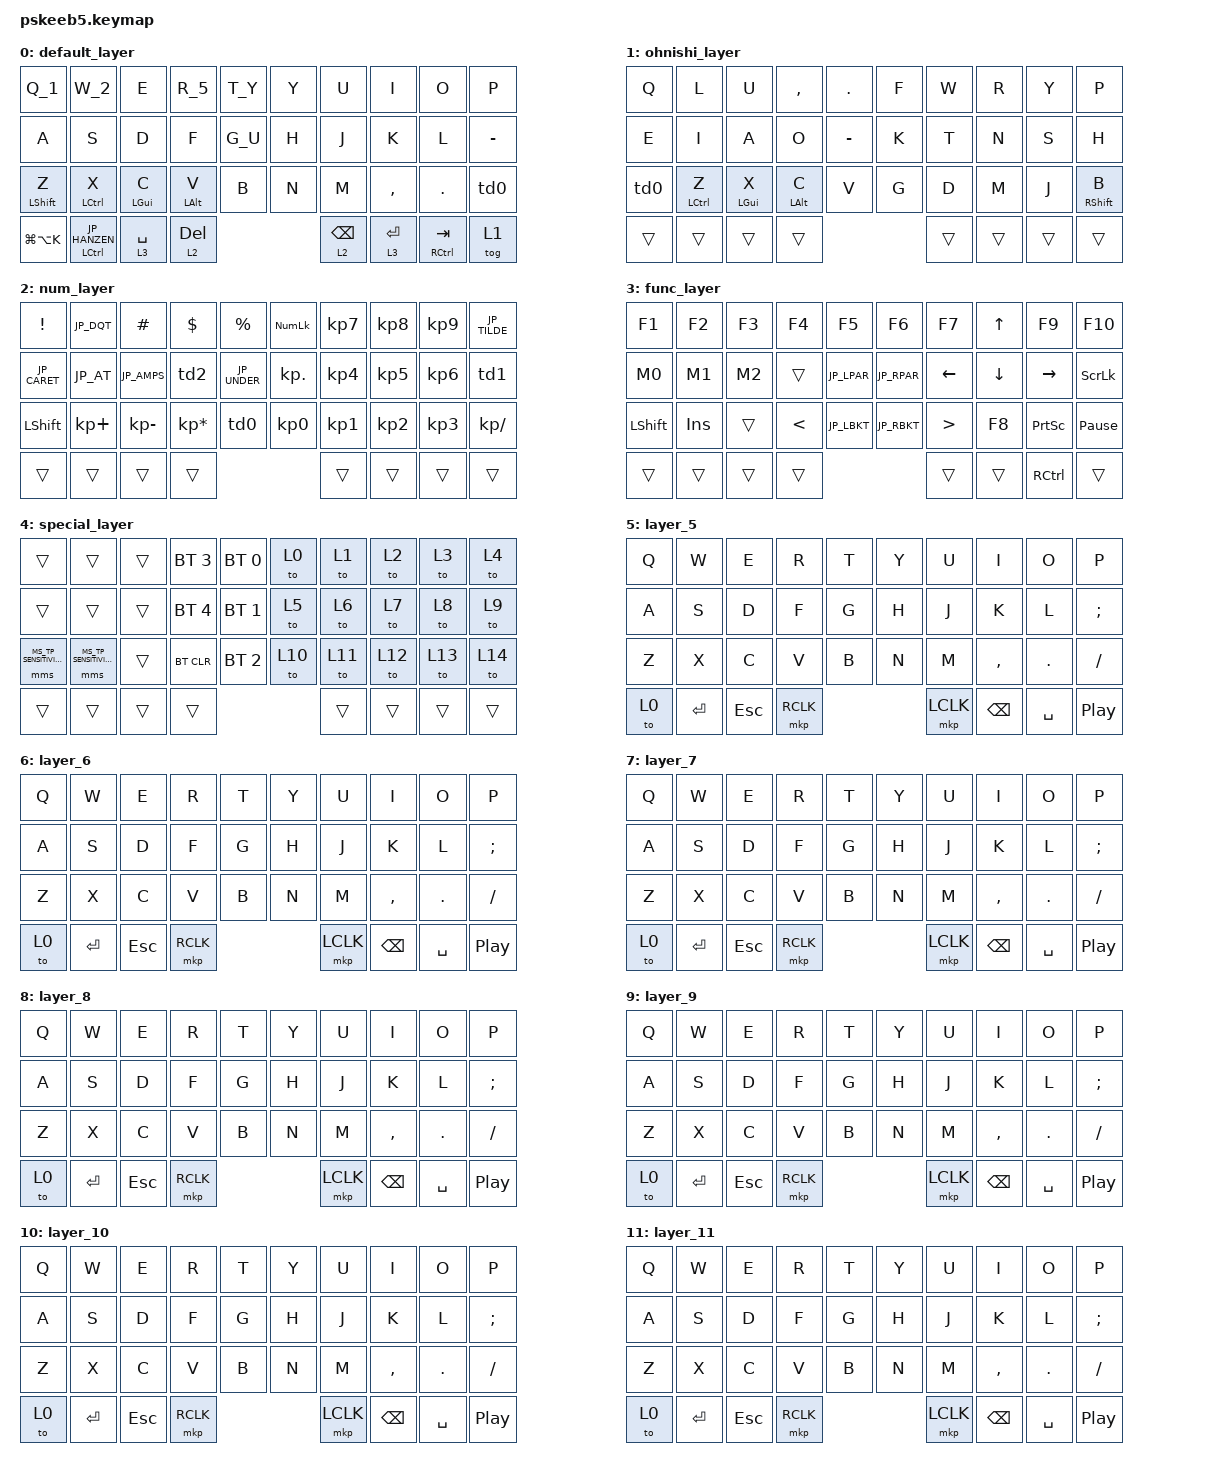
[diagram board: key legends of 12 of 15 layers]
// Copyright (c) 2022 The ZMK Contributors
// SPDX-License-Identifier: MIT

#include <behaviors.dtsi>
#include <dt-bindings/zmk/keys.h>
#include <dt-bindings/zmk/mouse.h>
#include <dt-bindings/zmk/bt.h>

// Home row mods macro
#define HRML(k1,k2,k3,k4) &ht LALT k1  &ht LSHFT k2  &ht LGUI k3  &ht LCTRL k4
#define HRMR(k1,k2,k3,k4) &ht RCTRL k1  &ht RGUI k2  &ht RSHFT k3  &ht RALT k4
#define LCS(keycode) APPLY_MODS(MOD_LCTL | MOD_LSFT, keycode)
#define LCG(keycode) APPLY_MODS(MOD_LCTL | MOD_LGUI, keycode)

// Rotary Endocer for mouse scrolling
#define ROT_MSC_VAL 280
#define ROT_MSC_SUP MOVE_Y(ROT_MSC_VAL)
#define ROT_MSC_SDN MOVE_Y(-ROT_MSC_VAL)
#define ROT_MSC_SLT MOVE_X(-ROT_MSC_VAL)
#define ROT_MSC_SRT MOVE_X(ROT_MSC_VAL)

// OS設定を日本語キーボードのまま使用するための変換定義
#define JP_DQT          AT                // "
#define JP_AMPS         CARET             // &
#define JP_SQT          AMPERSAND         // '
#define JP_EQUAL        UNDER             // =
#define JP_CARET        EQUAL             // ^
#define JP_YEN          0x89              // ¥
#define JP_PLUS         COLON             // +
#define JP_TILDE        PLUS              // ~
#define JP_PIPE         LS(0x89)          // |
#define JP_AT           LEFT_BRACKET      // @
#define JP_COLON        SINGLE_QUOTE      // :
#define JP_ASTRK        DOUBLE_QUOTES     // *
#define JP_GRAVE        LEFT_BRACE        // `
#define JP_UNDER        LS(0x87)          // _
#define JP_LBKT         RIGHT_BRACKET     // [
#define JP_RBKT         BACKSLASH         // ]
#define JP_LPAR         ASTERISK          // (
#define JP_RPAR         LEFT_PARENTHESIS  // )
#define JP_LBRC         RIGHT_BRACE       // {
#define JP_RBRC         PIPE              // }
#define JP_KANA         LANGUAGE_1        // かな
#define JP_EISU         LANGUAGE_2        // 英数
#define JP_HANZEN       GRAVE             // 半角/全角

#include <behaviors/mouse_setting.dtsi>
#include <dt-bindings/zmk/mouse_settings.h>
#define U_MSS_TP_S_I &mms MS_TP_SENSITIVITY_INCR
#define U_MSS_TP_S_D &mms MS_TP_SENSITIVITY_DECR

/ {
    behaviors {
        ht: hold_tap {
            display-name = "Hold Tap";
            label = "hold_tap";
            compatible = "zmk,behavior-hold-tap";
            #binding-cells = <2>;
            flavor = "balanced";
            tapping-term-ms = <220>;
            quick-tap-ms = <200>;
            // global-quick-tap;
            bindings = <&kp>, <&kp>;
        };
        lt: layer_tap {
            display-name = "Layer Tap";
            compatible = "zmk,behavior-hold-tap";
            label = "LAYER_TAP";
            #binding-cells = <2>;
            // flavor = "balanced";
            tapping-term-ms = <200>;
            quick-tap-ms = <200>;
            // global-quick-tap;
            bindings = <&mo>, <&kp>;
        };
        rot_msc: sensor_rotate_msc {
            compatible = "zmk,behavior-sensor-rotate-var";
            #sensor-binding-cells = <2>;
            bindings = <&msc>, <&msc>;
            tap-ms = <20>;
        };
        td0: tap_dance_0 {
            compatible = "zmk,behavior-tap-dance";
            #binding-cells = <0>;
            tapping-term-ms = <200>;
            bindings = <&ht LSHFT FSLH>, <&kp JP_YEN>;
        };
        td1: tap_dance_1 {
            compatible = "zmk,behavior-tap-dance";
            #binding-cells = <0>;
            tapping-term-ms = <200>;
            bindings = <&kp JP_COLON>, <&kp SEMI>;
        };
        td2: tap_dance_2 {
            compatible = "zmk,behavior-tap-dance";
            #binding-cells = <0>;
            tapping-term-ms = <200>;
            bindings = <&kp JP_SQT>, <&kp JP_GRAVE>;
        };
        Q_1: Q_ctrl1 {
            compatible = "zmk,behavior-mod-morph";
            #binding-cells = <0>;
            bindings = <&kp Q>, <&kp N1>;
            mods = <(MOD_LCTL|MOD_RCTL)>;
            keep-mods = <(MOD_LCTL|MOD_RCTL)>;
        };
        W_2: W_ctrl2 {
            compatible = "zmk,behavior-mod-morph";
            #binding-cells = <0>;
            bindings = <&kp W>, <&kp N2>;
            mods = <(MOD_LCTL|MOD_RCTL)>;
            keep-mods = <(MOD_LCTL|MOD_RCTL)>;
        };
        R_5: R_ctrl5 {
            compatible = "zmk,behavior-mod-morph";
            #binding-cells = <0>;
            bindings = <&kp R>, <&kp N5>;
            mods = <(MOD_LCTL|MOD_RCTL)>;
            keep-mods = <(MOD_LCTL|MOD_RCTL)>;
        };
        T_Y: T_ctrlY {
            compatible = "zmk,behavior-mod-morph";
            #binding-cells = <0>;
            bindings = <&kp T>, <&kp Y>;
            mods = <(MOD_LCTL|MOD_RCTL)>;
            keep-mods = <(MOD_LCTL|MOD_RCTL)>;
        };
        G_U: G_ctrlU {
            compatible = "zmk,behavior-mod-morph";
            #binding-cells = <0>;
            bindings = <&kp G>, <&kp U>;
            mods = <(MOD_LCTL|MOD_RCTL)>;
            keep-mods = <(MOD_LCTL|MOD_RCTL)>;
        };
        //gresc: grave_escape {
        //    compatible = "zmk,behavior-mod-morph";
        //    #binding-cells = <0>;
        //    bindings = <&kp ESC>, <&kp GRAVE>;
        //    mods = <(MOD_LGUI|MOD_LSFT|MOD_RGUI|MOD_RSFT)>;
        //};
    };


    combos {
        compatible = "zmk,combos";
        //combo_tab {
        //    timeout-ms = <50>;
        //    key-positions = <2 3>;
        //    bindings = <&kp TAB>;
        //};
        combo_esc {
            timeout-ms = <50>;
            key-positions = <0 1>;
            bindings = <&kp ESC>;
        };
        left_click {
            timeout-ms = <50>;
            key-positions = <34 35>;
            bindings = <&mkp LCLK>;
        };
        right_click {
            timeout-ms = <50>;
            key-positions = <35 36>;
            bindings = <&mkp RCLK>;
        };
        middle_click {
            timeout-ms = <50>;
            key-positions = <33 34>;
            bindings = <&mkp MCLK>;
        };
    };

    conditional_layers {
        compatible = "zmk,conditional-layers";
        special_layer {
            if-layers = <2 3>;
            then-layer = <4>;
        };
    };

    macros {
        //win_sleep: win_sleep {
        //    compatible = "zmk,behavior-macro";
        //    #binding-cells = <0>;
        //    bindings
        //        = <&kp LG(X)>   // Opens the quick menu
        //        , <&macro_wait_time 50>    // Small delay for menu
        //        , <&kp U>       // "Shut down or sign out"
        //        , <&macro_wait_time 50>    // Delay
        //        , <&kp S>;      // "Sleep"
        //};
        M0: M0 {
            compatible = "zmk,behavior-macro";
            #binding-cells = <0>;
            bindings
                = <&kp INT5 &kp N6 &kp N1 &kp N0 &kp N8 &kp N1 &kp N1>;
        };
        M1: M1 {
            compatible = "zmk,behavior-macro";
            #binding-cells = <0>;
            bindings
                = <&kp INT5 &kp LS(R) &kp EXCL &kp K &kp K &kp A &kp N &kp A &kp K &kp N0>;
        };
        M2: M2 {
            compatible = "zmk,behavior-macro";
            #binding-cells = <0>;
            wait-ms = <10>;
            tap-ms = <10>;
            bindings
                = <&kp INT5 &kp W &kp A &kp T &kp A &kp N &kp A &kp B &kp E &kp DOT>
                , <&kp N5 &kp N3 &kp C &kp DOT &kp Y &kp U &kp JP_AT>
                , <&kp J &kp P &kp DOT>
                , <&kp N &kp I &kp P &kp P &kp O &kp N &kp S &kp T &kp E &kp E &kp L &kp DOT>
                , <&kp C &kp O &kp M>;
        };
    };

    keymap {
        compatible = "zmk,keymap";
        default_layer {
            bindings = <
        //╭──────────┬──────────┬──────────┬──────────┬──────────╮   ╭──────────┬──────────┬──────────┬──────────┬──────────╮
        //│  Q       │  W       │  E       │  R       │  T       │   │  Y       │  U       │  I       │  O       │  P       │
            &Q_1       &W_2       &kp E      &R_5       &T_Y           &kp Y      &kp U      &kp I      &kp O      &kp P
        //├──────────┼──────────┼──────────┼──────────┼──────────┤   ├──────────┼──────────┼──────────┼──────────┼──────────┤
        //│  A       │  S       │  D       │  F       │  G       │   │  H       │  J       │  K       │  L       │ - =      │
            &kp A      &kp S      &kp D      &kp F      &G_U           &kp H      &kp J      &kp K      &kp L      &kp MINUS
        //├──────────┼──────────┼──────────┼──────────┼──────────┤   ├──────────┼──────────┼──────────┼──────────┼──────────┤
        //│  Z       │  X       │  C       │  V       │  B       │   │  N       │  M       │ , <      │ . >      │ / ? \    │
           &ht LSHFT Z &ht LCTRL X &ht LGUI C &ht LALT V &kp B         &kp N      &kp M      &kp COMMA &kp DOT     &td0
        //╰──────────┴──────────┴──────────┼──────────┼──────────┤   ├──────────┼──────────┼──────────┴──────────┴──────────╯
             &kp LG(LA(K))  &ht LCTRL JP_HANZEN &lt 3 SPACE &lt 2 DEL     &lt 2 BSPC &lt 3 ENTER &ht RCTRL TAB &tog 1
        //                                 ╰──────────┴──────────╯   ╰──────────┴──────────╯
            >;
            // sensor-bindings = <&rot_msc ROT_MSC_SUP ROT_MSC_SDN &rot_msc ROT_MSC_SLT ROT_MSC_SRT>;
            sensor-bindings = <&inc_dec_kp C_VOL_DN C_VOL_UP &rot_msc ROT_MSC_SDN ROT_MSC_SUP>;
        };

        ohnishi_layer {
            bindings = <
        //╭──────────┬──────────┬──────────┬──────────┬──────────╮   ╭──────────┬──────────┬──────────┬──────────┬──────────╮
        //│  Q       │  L       │  U       │ , <      │ . >      │   │  F       │  W       │  R       │  Y       │  P       │
            &kp Q      &kp L      &kp U      &kp COMMA  &kp DOT        &kp F      &kp W      &kp R      &kp Y      &kp P
        //├──────────┼──────────┼──────────┼──────────┼──────────┤   ├──────────┼──────────┼──────────┼──────────┼──────────┤
        //│  E       │  I       │  A       │  O       │ - =      │   │  K       │  T       │  N       │  S       │  H       │
            &kp E      &kp I      &kp A      &kp O      &kp MINUS      &kp K      &kp T      &kp N      &kp S      &kp H
        //├──────────┼──────────┼──────────┼──────────┼──────────┤   ├──────────┼──────────┼──────────┼──────────┼──────────┤
        //│ / ? \    │  Z       │  X       │  C       │  V       │   │  G       │  D       │  M       │  J       │  B       │
            &td0       &ht LCTRL Z &ht LGUI X &ht LALT C &kp V         &kp G      &kp D      &kp M      &kp J     &ht RSHFT B
        //╰──────────┴──────────┴──────────┼──────────┼──────────┤   ├──────────┼──────────┼──────────┴──────────┴──────────╯
                       &trans     &trans     &trans     &trans         &trans     &trans     &trans     &trans  
        //                                 ╰──────────┴──────────╯   ╰──────────┴──────────╯
            >;
            // sensor-bindings = <&rot_msc ROT_MSC_SUP ROT_MSC_SDN &rot_msc ROT_MSC_SLT ROT_MSC_SRT>;
            sensor-bindings = <&inc_dec_kp C_VOL_DN C_VOL_UP &rot_msc ROT_MSC_SDN ROT_MSC_SUP>;
        };

        num_layer {
            bindings = <
        //╭──────────┬──────────┬──────────┬──────────┬──────────╮   ╭──────────┬──────────┬──────────┬──────────┬──────────╮
        //│  !       │  "       │  #       │  $       │  %       │   │ NUM LOCK │  7       │  8       │  9       │  ~       │
            &kp EXCL  &kp JP_DQT  &kp HASH   &kp DLLR   &kp PRCNT      &kp KP_NUM &kp KP_N7  &kp KP_N8  &kp KP_N9  &kp JP_TILDE
        //├──────────┼──────────┼──────────┼──────────┼──────────┤   ├──────────┼──────────┼──────────┼──────────┼──────────┤
        //│  ^       │  @       │  &       │  ' `     │  _       │   │  .       │  4       │  5       │  6       │  : ;     │
          &kp JP_CARET &kp JP_AT  &kp JP_AMPS &td2      &kp JP_UNDER   &kp KP_DOT &kp KP_N4  &kp KP_N5  &kp KP_N6  &td1
        //├──────────┼──────────┼──────────┼──────────┼──────────┤   ├──────────┼──────────┼──────────┼──────────┼──────────┤
        //│  LSHIFT  │  +       │  -       │  *       │  / ? \   │   │  0       │  1       │  2       │  3       │  /       │
            &kp LSHFT  &kp KP_PLUS &kp KP_MINUS &kp KP_MULTIPLY &td0   &kp KP_N0  &kp KP_N1  &kp KP_N2  &kp KP_N3  &kp KP_DIVIDE 
        //╰──────────┴──────────┴──────────┼──────────┼──────────┤   ├──────────┼──────────┼──────────┴──────────┴──────────╯
                       &trans     &trans     &trans     &trans         &trans     &trans     &trans     &trans
        //                                 ╰──────────┴──────────╯   ╰──────────┴──────────╯
            >;
            sensor-bindings = <&inc_dec_kp C_VOL_DN C_VOL_UP &inc_dec_kp LEFT RIGHT>;
        };

        func_layer {
            bindings = <
        //╭──────────┬──────────┬──────────┬──────────┬──────────╮   ╭──────────┬──────────┬──────────┬──────────┬──────────╮
        //│ F1       │ F2       │ F3       │ F4       │ F5       │   │ F6       │ F7       │ Up       │ F9       │ F10      │
            &kp F1     &kp F2     &kp F3     &kp F4     &kp F5         &kp F6     &kp F7     &kp UP     &kp F9     &kp F10 
        //├──────────┼──────────┼──────────┼──────────┼──────────┤   ├──────────┼──────────┼──────────┼──────────┼──────────┤
        //│ M0       │ M1       │ M2       │          │  (       │   │  )       │ LEFT     │ DOWN     │ RIGHT    │ ScrLock  │
            &M0        &M1        &M2        &trans     &kp JP_LPAR   &kp JP_RPAR &kp LEFT   &kp DOWN   &kp RIGHT  &kp SLCK 
        //├──────────┼──────────┼──────────┼──────────┼──────────┤   ├──────────┼──────────┼──────────┼──────────┼──────────┤
        //│ LSHIFT   │ INS      │          │  <       │  [       │   │  ]       │  >       │ F8       │ PrtScr   │ Pause    │
            &kp LSHFT  &kp INS    &trans     &kp LT     &kp JP_LBKT   &kp JP_RBKT &kp GT     &kp F8     &kp PSCRN  &kp PAUSE_BREAK
        //╰──────────┴──────────┴──────────┼──────────┼──────────┤   ├──────────┼──────────┼──────────┴──────────┴──────────╯
                        &trans     &trans    &trans     &trans         &trans     &trans     &kp RCTRL  &trans
        //                                 ╰──────────┴──────────╯   ╰──────────┴──────────╯
            >;
            sensor-bindings = <&inc_dec_kp C_VOL_DN C_VOL_UP &inc_dec_kp LEFT RIGHT>;
        };

        special_layer {
            bindings = <
        //╭──────────────┬──────────────┬──────────┬─────────────┬────────────╮   ╭──────────┬──────────┬──────────┬──────────┬──────────╮
        //│              │              │          │ PROFILE 3   │PROFILE 0   │   │          │          │          │          │          │
           &trans           &trans        &trans     &bt BT_SEL 3 &bt BT_SEL 0      &to 0     &to 1       &to 2      &to 3      &to 4
        //├──────────────┼──────────────┼──────────┼─────────────┼────────────┤   ├──────────┼──────────┼──────────┼──────────┼──────────┤
        //│              │              │          │ PROFILE 4   │PROFILE 1   │   │          │          │          │          │          │
           &trans           &trans        &trans    &bt BT_SEL 4 &bt BT_SEL 1       &to 5     &to 6       &to 7      &to 8      &to 9
        //├──────────────┼──────────────┼──────────┼─────────────┼────────────┤   ├──────────┼──────────┼──────────┼──────────┼──────────┤
        //│              │              │          │ CLEAR BT    │PROFILE 2   │   │          │          │          │          │          │
           U_MSS_TP_S_D    U_MSS_TP_S_I   &trans   &bt BT_CLR   &bt BT_SEL 2        &to 10    &to 11      &to 12     &to 13     &to 14
        //╰──────────────┴──────────────┴──────────┼─────────────┼────────────┤   ├──────────┼──────────┼──────────┴──────────┴──────────╯
                       &trans     &trans    &trans     &trans             &trans     &trans     &trans     &trans
        //                                 ╰─────────────┴──────────╯   ╰──────────┴──────────╯
            >;
            sensor-bindings = <&inc_dec_kp C_VOL_DN C_VOL_UP &inc_dec_kp LEFT RIGHT>;
        };

        layer_5 {
            bindings = <
        //╭──────────┬──────────┬──────────┬──────────┬──────────╮   ╭──────────┬──────────┬──────────┬──────────┬──────────╮
        //│  Q       │  W       │  E       │  R       │  T       │   │  Y       │  U       │  I       │  O       │  P       │
            &kp Q      &kp W      &kp E      &kp R      &kp T          &kp Y      &kp U      &kp I      &kp O      &kp P
        //├──────────┼──────────┼──────────┼──────────┼──────────┤   ├──────────┼──────────┼──────────┼──────────┼──────────┤
        //│  A       │  S       │  D       │  F       │  G       │   │  H       │  J       │  K       │  L       │ ; :      │
            &kp A      &kp S      &kp D      &kp F      &kp G          &kp H      &kp J      &kp K      &kp L      &kp SEMI
        //├──────────┼──────────┼──────────┼──────────┼──────────┤   ├──────────┼──────────┼──────────┼──────────┼──────────┤
        //│  Z       │  X       │  C       │  V       │  B       │   │  N       │  M       │ , <      │ . >      │ / ?      │
            &kp Z      &kp X      &kp C      &kp V      &kp B          &kp N      &kp M      &kp COMMA  &kp DOT    &kp FSLH
        //╰──────────┴──────────┴──────────┼──────────┼──────────┤   ├──────────┼──────────┼──────────┴──────────┴──────────╯
                       &to 0      &kp ENTER  &kp ESC    &mkp RCLK      &mkp LCLK  &kp BSPC   &kp SPACE  &kp C_PP
        //                                 ╰──────────┴──────────╯   ╰──────────┴──────────╯
            >;
            sensor-bindings = <&inc_dec_kp C_VOL_DN C_VOL_UP &inc_dec_kp LEFT RIGHT>;
        };

        layer_6 {
            bindings = <
        //╭──────────┬──────────┬──────────┬──────────┬──────────╮   ╭──────────┬──────────┬──────────┬──────────┬──────────╮
        //│  Q       │  W       │  E       │  R       │  T       │   │  Y       │  U       │  I       │  O       │  P       │
            &kp Q      &kp W      &kp E      &kp R      &kp T          &kp Y      &kp U      &kp I      &kp O      &kp P
        //├──────────┼──────────┼──────────┼──────────┼──────────┤   ├──────────┼──────────┼──────────┼──────────┼──────────┤
        //│  A       │  S       │  D       │  F       │  G       │   │  H       │  J       │  K       │  L       │ ; :      │
            &kp A      &kp S      &kp D      &kp F      &kp G          &kp H      &kp J      &kp K      &kp L      &kp SEMI
        //├──────────┼──────────┼──────────┼──────────┼──────────┤   ├──────────┼──────────┼──────────┼──────────┼──────────┤
        //│  Z       │  X       │  C       │  V       │  B       │   │  N       │  M       │ , <      │ . >      │ / ?      │
            &kp Z      &kp X      &kp C      &kp V      &kp B          &kp N      &kp M      &kp COMMA  &kp DOT    &kp FSLH
        //╰──────────┴──────────┴──────────┼──────────┼──────────┤   ├──────────┼──────────┼──────────┴──────────┴──────────╯
                       &to 0      &kp ENTER  &kp ESC    &mkp RCLK      &mkp LCLK  &kp BSPC   &kp SPACE  &kp C_PP
        //                                 ╰──────────┴──────────╯   ╰──────────┴──────────╯
            >;
            sensor-bindings = <&inc_dec_kp C_VOL_DN C_VOL_UP &inc_dec_kp LEFT RIGHT>;
        };

        layer_7 {
            bindings = <
        //╭──────────┬──────────┬──────────┬──────────┬──────────╮   ╭──────────┬──────────┬──────────┬──────────┬──────────╮
        //│  Q       │  W       │  E       │  R       │  T       │   │  Y       │  U       │  I       │  O       │  P       │
            &kp Q      &kp W      &kp E      &kp R      &kp T          &kp Y      &kp U      &kp I      &kp O      &kp P
        //├──────────┼──────────┼──────────┼──────────┼──────────┤   ├──────────┼──────────┼──────────┼──────────┼──────────┤
        //│  A       │  S       │  D       │  F       │  G       │   │  H       │  J       │  K       │  L       │ ; :      │
            &kp A      &kp S      &kp D      &kp F      &kp G          &kp H      &kp J      &kp K      &kp L      &kp SEMI
        //├──────────┼──────────┼──────────┼──────────┼──────────┤   ├──────────┼──────────┼──────────┼──────────┼──────────┤
        //│  Z       │  X       │  C       │  V       │  B       │   │  N       │  M       │ , <      │ . >      │ / ?      │
            &kp Z      &kp X      &kp C      &kp V      &kp B          &kp N      &kp M      &kp COMMA  &kp DOT    &kp FSLH
        //╰──────────┴──────────┴──────────┼──────────┼──────────┤   ├──────────┼──────────┼──────────┴──────────┴──────────╯
                       &to 0      &kp ENTER  &kp ESC    &mkp RCLK      &mkp LCLK  &kp BSPC   &kp SPACE  &kp C_PP
        //                                 ╰──────────┴──────────╯   ╰──────────┴──────────╯
            >;
            sensor-bindings = <&inc_dec_kp C_VOL_DN C_VOL_UP &inc_dec_kp LEFT RIGHT>;
        };

        layer_8 {
            bindings = <
        //╭──────────┬──────────┬──────────┬──────────┬──────────╮   ╭──────────┬──────────┬──────────┬──────────┬──────────╮
        //│  Q       │  W       │  E       │  R       │  T       │   │  Y       │  U       │  I       │  O       │  P       │
            &kp Q      &kp W      &kp E      &kp R      &kp T          &kp Y      &kp U      &kp I      &kp O      &kp P
        //├──────────┼──────────┼──────────┼──────────┼──────────┤   ├──────────┼──────────┼──────────┼──────────┼──────────┤
        //│  A       │  S       │  D       │  F       │  G       │   │  H       │  J       │  K       │  L       │ ; :      │
            &kp A      &kp S      &kp D      &kp F      &kp G          &kp H      &kp J      &kp K      &kp L      &kp SEMI
        //├──────────┼──────────┼──────────┼──────────┼──────────┤   ├──────────┼──────────┼──────────┼──────────┼──────────┤
        //│  Z       │  X       │  C       │  V       │  B       │   │  N       │  M       │ , <      │ . >      │ / ?      │
            &kp Z      &kp X      &kp C      &kp V      &kp B          &kp N      &kp M      &kp COMMA  &kp DOT    &kp FSLH
        //╰──────────┴──────────┴──────────┼──────────┼──────────┤   ├──────────┼──────────┼──────────┴──────────┴──────────╯
                       &to 0      &kp ENTER  &kp ESC    &mkp RCLK      &mkp LCLK  &kp BSPC   &kp SPACE  &kp C_PP
        //                                 ╰──────────┴──────────╯   ╰──────────┴──────────╯
            >;
            sensor-bindings = <&inc_dec_kp C_VOL_DN C_VOL_UP &inc_dec_kp LEFT RIGHT>;
        };

        layer_9 {
            bindings = <
        //╭──────────┬──────────┬──────────┬──────────┬──────────╮   ╭──────────┬──────────┬──────────┬──────────┬──────────╮
        //│  Q       │  W       │  E       │  R       │  T       │   │  Y       │  U       │  I       │  O       │  P       │
            &kp Q      &kp W      &kp E      &kp R      &kp T          &kp Y      &kp U      &kp I      &kp O      &kp P
        //├──────────┼──────────┼──────────┼──────────┼──────────┤   ├──────────┼──────────┼──────────┼──────────┼──────────┤
        //│  A       │  S       │  D       │  F       │  G       │   │  H       │  J       │  K       │  L       │ ; :      │
            &kp A      &kp S      &kp D      &kp F      &kp G          &kp H      &kp J      &kp K      &kp L      &kp SEMI
        //├──────────┼──────────┼──────────┼──────────┼──────────┤   ├──────────┼──────────┼──────────┼──────────┼──────────┤
        //│  Z       │  X       │  C       │  V       │  B       │   │  N       │  M       │ , <      │ . >      │ / ?      │
            &kp Z      &kp X      &kp C      &kp V      &kp B          &kp N      &kp M      &kp COMMA  &kp DOT    &kp FSLH
        //╰──────────┴──────────┴──────────┼──────────┼──────────┤   ├──────────┼──────────┼──────────┴──────────┴──────────╯
                       &to 0      &kp ENTER  &kp ESC    &mkp RCLK      &mkp LCLK  &kp BSPC   &kp SPACE  &kp C_PP
        //                                 ╰──────────┴──────────╯   ╰──────────┴──────────╯
            >;
            sensor-bindings = <&inc_dec_kp C_VOL_DN C_VOL_UP &inc_dec_kp LEFT RIGHT>;
        };

        layer_10 {
            bindings = <
        //╭──────────┬──────────┬──────────┬──────────┬──────────╮   ╭──────────┬──────────┬──────────┬──────────┬──────────╮
        //│  Q       │  W       │  E       │  R       │  T       │   │  Y       │  U       │  I       │  O       │  P       │
            &kp Q      &kp W      &kp E      &kp R      &kp T          &kp Y      &kp U      &kp I      &kp O      &kp P
        //├──────────┼──────────┼──────────┼──────────┼──────────┤   ├──────────┼──────────┼──────────┼──────────┼──────────┤
        //│  A       │  S       │  D       │  F       │  G       │   │  H       │  J       │  K       │  L       │ ; :      │
            &kp A      &kp S      &kp D      &kp F      &kp G          &kp H      &kp J      &kp K      &kp L      &kp SEMI
        //├──────────┼──────────┼──────────┼──────────┼──────────┤   ├──────────┼──────────┼──────────┼──────────┼──────────┤
        //│  Z       │  X       │  C       │  V       │  B       │   │  N       │  M       │ , <      │ . >      │ / ?      │
            &kp Z      &kp X      &kp C      &kp V      &kp B          &kp N      &kp M      &kp COMMA  &kp DOT    &kp FSLH
        //╰──────────┴──────────┴──────────┼──────────┼──────────┤   ├──────────┼──────────┼──────────┴──────────┴──────────╯
                       &to 0      &kp ENTER  &kp ESC    &mkp RCLK      &mkp LCLK  &kp BSPC   &kp SPACE  &kp C_PP
        //                                 ╰──────────┴──────────╯   ╰──────────┴──────────╯
            >;
            sensor-bindings = <&inc_dec_kp C_VOL_DN C_VOL_UP &inc_dec_kp LEFT RIGHT>;
        };

        layer_11 {
            bindings = <
        //╭──────────┬──────────┬──────────┬──────────┬──────────╮   ╭──────────┬──────────┬──────────┬──────────┬──────────╮
        //│  Q       │  W       │  E       │  R       │  T       │   │  Y       │  U       │  I       │  O       │  P       │
            &kp Q      &kp W      &kp E      &kp R      &kp T          &kp Y      &kp U      &kp I      &kp O      &kp P
        //├──────────┼──────────┼──────────┼──────────┼──────────┤   ├──────────┼──────────┼──────────┼──────────┼──────────┤
        //│  A       │  S       │  D       │  F       │  G       │   │  H       │  J       │  K       │  L       │ ; :      │
            &kp A      &kp S      &kp D      &kp F      &kp G          &kp H      &kp J      &kp K      &kp L      &kp SEMI
        //├──────────┼──────────┼──────────┼──────────┼──────────┤   ├──────────┼──────────┼──────────┼──────────┼──────────┤
        //│  Z       │  X       │  C       │  V       │  B       │   │  N       │  M       │ , <      │ . >      │ / ?      │
            &kp Z      &kp X      &kp C      &kp V      &kp B          &kp N      &kp M      &kp COMMA  &kp DOT    &kp FSLH
        //╰──────────┴──────────┴──────────┼──────────┼──────────┤   ├──────────┼──────────┼──────────┴──────────┴──────────╯
                       &to 0      &kp ENTER  &kp ESC    &mkp RCLK      &mkp LCLK  &kp BSPC   &kp SPACE  &kp C_PP
        //                                 ╰──────────┴──────────╯   ╰──────────┴──────────╯
            >;
            sensor-bindings = <&inc_dec_kp C_VOL_DN C_VOL_UP &inc_dec_kp LEFT RIGHT>;
        };

        layer_12 {
            bindings = <
        //╭──────────┬──────────┬──────────┬──────────┬──────────╮   ╭──────────┬──────────┬──────────┬──────────┬──────────╮
        //│  Q       │  W       │  E       │  R       │  T       │   │  Y       │  U       │  I       │  O       │  P       │
            &kp Q      &kp W      &kp E      &kp R      &kp T          &kp Y      &kp U      &kp I      &kp O      &kp P
        //├──────────┼──────────┼──────────┼──────────┼──────────┤   ├──────────┼──────────┼──────────┼──────────┼──────────┤
        //│  A       │  S       │  D       │  F       │  G       │   │  H       │  J       │  K       │  L       │ ; :      │
            &kp A      &kp S      &kp D      &kp F      &kp G          &kp H      &kp J      &kp K      &kp L      &kp SEMI
        //├──────────┼──────────┼──────────┼──────────┼──────────┤   ├──────────┼──────────┼──────────┼──────────┼──────────┤
        //│  Z       │  X       │  C       │  V       │  B       │   │  N       │  M       │ , <      │ . >      │ / ?      │
            &kp Z      &kp X      &kp C      &kp V      &kp B          &kp N      &kp M      &kp COMMA  &kp DOT    &kp FSLH
        //╰──────────┴──────────┴──────────┼──────────┼──────────┤   ├──────────┼──────────┼──────────┴──────────┴──────────╯
                       &to 0      &kp ENTER  &kp ESC    &mkp RCLK      &mkp LCLK  &kp BSPC   &kp SPACE  &kp C_PP
        //                                 ╰──────────┴──────────╯   ╰──────────┴──────────╯
            >;
            sensor-bindings = <&inc_dec_kp C_VOL_DN C_VOL_UP &inc_dec_kp LEFT RIGHT>;
        };

        layer_13 {
            bindings = <
        //╭──────────┬──────────┬──────────┬──────────┬──────────╮   ╭──────────┬──────────┬──────────┬──────────┬──────────╮
        //│  Q       │  W       │  E       │  R       │  T       │   │  Y       │  U       │  I       │  O       │  P       │
            &kp Q      &kp W      &kp E      &kp R      &kp T          &kp Y      &kp U      &kp I      &kp O      &kp P
        //├──────────┼──────────┼──────────┼──────────┼──────────┤   ├──────────┼──────────┼──────────┼──────────┼──────────┤
        //│  A       │  S       │  D       │  F       │  G       │   │  H       │  J       │  K       │  L       │ ; :      │
            &kp A      &kp S      &kp D      &kp F      &kp G          &kp H      &kp J      &kp K      &kp L      &kp SEMI
        //├──────────┼──────────┼──────────┼──────────┼──────────┤   ├──────────┼──────────┼──────────┼──────────┼──────────┤
        //│  Z       │  X       │  C       │  V       │  B       │   │  N       │  M       │ , <      │ . >      │ / ?      │
            &kp Z      &kp X      &kp C      &kp V      &kp B          &kp N      &kp M      &kp COMMA  &kp DOT    &kp FSLH
        //╰──────────┴──────────┴──────────┼──────────┼──────────┤   ├──────────┼──────────┼──────────┴──────────┴──────────╯
                       &to 0      &kp ENTER  &kp ESC    &mkp RCLK      &mkp LCLK  &kp BSPC   &kp SPACE  &kp C_PP
        //                                 ╰──────────┴──────────╯   ╰──────────┴──────────╯
            >;
            sensor-bindings = <&inc_dec_kp C_VOL_DN C_VOL_UP &inc_dec_kp LEFT RIGHT>;
        };

        layer_14 {
            bindings = <
        //╭──────────┬──────────┬──────────┬──────────┬──────────╮   ╭──────────┬──────────┬──────────┬──────────┬──────────╮
        //│  Q       │  W       │  E       │  R       │  T       │   │  Y       │  U       │  I       │  O       │  P       │
            &kp Q      &kp W      &kp E      &kp R      &kp T          &kp Y      &kp U      &kp I      &kp O      &kp P
        //├──────────┼──────────┼──────────┼──────────┼──────────┤   ├──────────┼──────────┼──────────┼──────────┼──────────┤
        //│  A       │  S       │  D       │  F       │  G       │   │  H       │  J       │  K       │  L       │ ; :      │
            &kp A      &kp S      &kp D      &kp F      &kp G          &kp H      &kp J      &kp K      &kp L      &kp SEMI
        //├──────────┼──────────┼──────────┼──────────┼──────────┤   ├──────────┼──────────┼──────────┼──────────┼──────────┤
        //│  Z       │  X       │  C       │  V       │  B       │   │  N       │  M       │ , <      │ . >      │ / ?      │
            &kp Z      &kp X      &kp C      &kp V      &kp B          &kp N      &kp M      &kp COMMA  &kp DOT    &kp FSLH
        //╰──────────┴──────────┴──────────┼──────────┼──────────┤   ├──────────┼──────────┼──────────┴──────────┴──────────╯
                       &to 0      &kp ENTER  &kp ESC    &mkp RCLK      &mkp LCLK  &kp BSPC   &kp SPACE  &kp C_PP
        //                                 ╰──────────┴──────────╯   ╰──────────┴──────────╯
            >;
            sensor-bindings = <&inc_dec_kp C_VOL_DN C_VOL_UP &inc_dec_kp LEFT RIGHT>;
        };
    };
};
